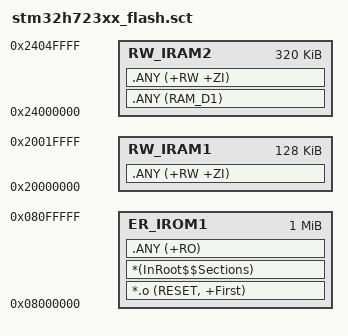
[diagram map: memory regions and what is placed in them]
; STM32H723: DTCM 给普通变量，AXI SRAM 给 UART DMA 缓冲区
; DMA1/DMA2 无法访问 0x20000000 DTCM

LR_IROM1 0x08000000 0x00100000  {
  ER_IROM1 0x08000000 0x00100000  {
   *.o (RESET, +First)
   *(InRoot$$Sections)
   .ANY (+RO)
  }
  RW_IRAM1 0x20000000 0x00020000  {  ; DTCM
   .ANY (+RW +ZI)
  }
  RW_IRAM2 0x24000000 0x00050000  {  ; AXI SRAM
   .ANY (RAM_D1)
   .ANY (+RW +ZI)
  }
}
